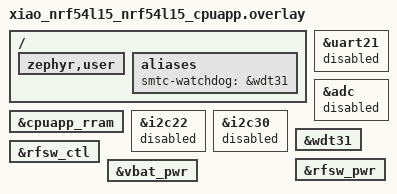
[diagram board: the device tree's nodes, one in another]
/*
 * Copyright (c) 2024 Semtech Corporation
 *
 * SPDX-License-Identifier: Apache-2.0
 */

/ {
	/*
	 * Host UART auto-selected from chosen zephyr,console (uart20 = USB serial,
	 * set by the base board DTS); carries trace + data for python_bridge.py.
	 */
	zephyr,user {
		/* PINS used for the HW modem sample. */
	};

	aliases {
		smtc-watchdog = &wdt31;
	};
};

//Label for flash controller (needed cause we need properties, and we grab alias in user code)
smtc_flash: &cpuapp_rram {};

// uart20 (USB serial / console) is already enabled @115200 by the base board DTS.
// Just turn off the unused header UART.
&uart21 {
	status = "disabled";
};

&adc {
	status = "disabled";
};

&i2c22 {
	status = "disabled";
};

&i2c30 {
	status = "disabled";
};

&wdt31 {
	status = "okay";
};

// Override xiao_nrf54l15 default configuration for USP applications
// Disable boot-on for RF switch regulators to save power

&rfsw_ctl {
	/delete-property/ regulator-boot-on;
};

&rfsw_pwr {
	/delete-property/ regulator-boot-on;
};

&vbat_pwr {
	/delete-property/ regulator-boot-on;
};
